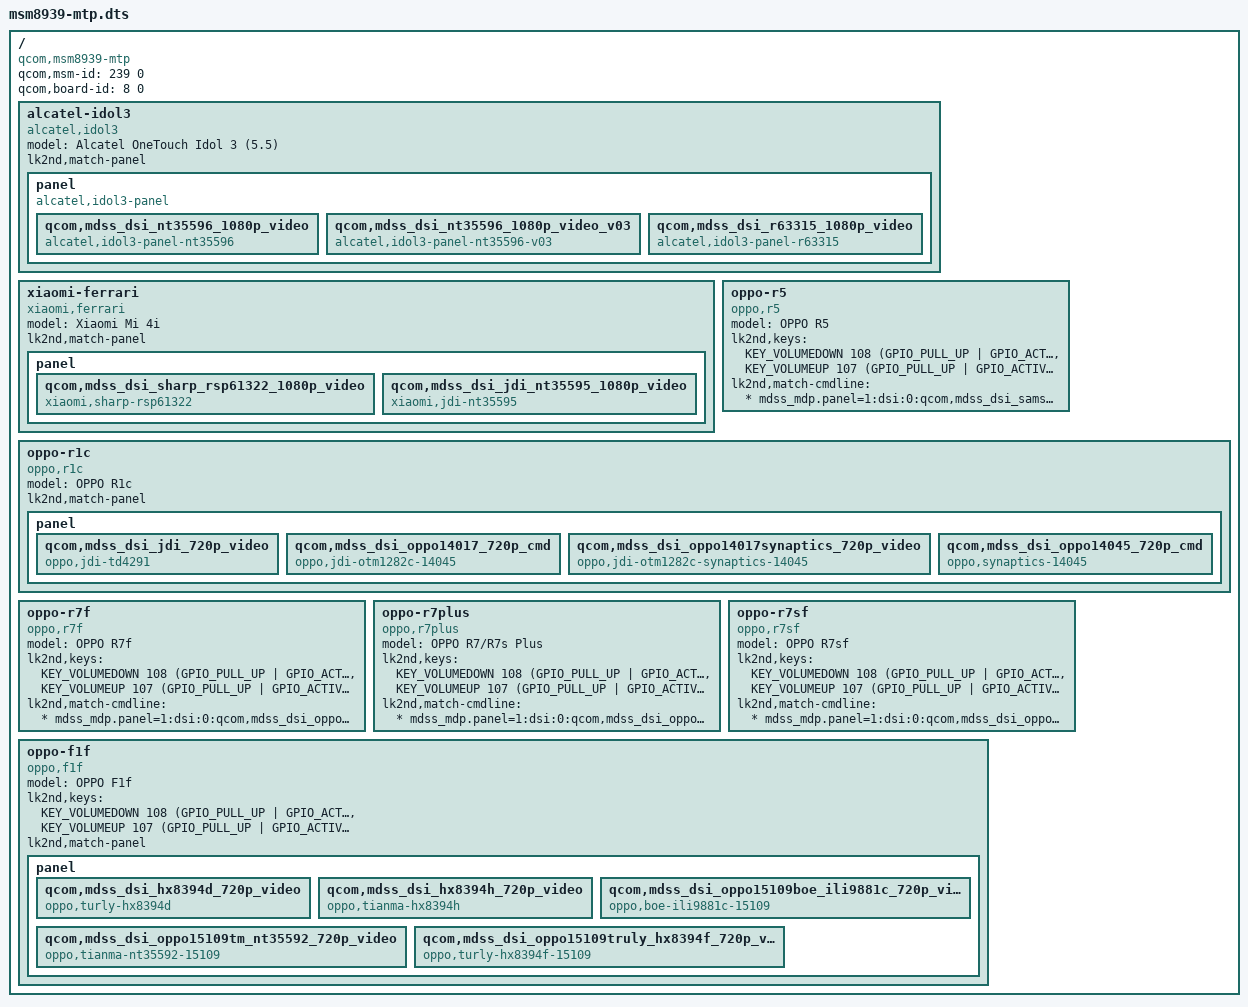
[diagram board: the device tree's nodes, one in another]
// SPDX-License-Identifier: GPL-2.0-only

/dts-v1/;

#include <skeleton.dtsi>
#include <lk2nd.h>

/ {
	compatible = "qcom,msm8939-mtp", "qcom,msm8939";
	qcom,msm-id = <239 0>;
	qcom,board-id = <8 0>;

	alcatel-idol3 {
		model = "Alcatel OneTouch Idol 3 (5.5)";
		compatible = "alcatel,idol3", "qcom,msm8939", "lk2nd,device";
		lk2nd,match-panel;

		panel {
			compatible = "alcatel,idol3-panel";

			qcom,mdss_dsi_nt35596_1080p_video {
				compatible = "alcatel,idol3-panel-nt35596";
			};
			qcom,mdss_dsi_nt35596_1080p_video_v03 {
				compatible = "alcatel,idol3-panel-nt35596-v03";
			};
			qcom,mdss_dsi_r63315_1080p_video {
				compatible = "alcatel,idol3-panel-r63315";
			};
		};
	};

	xiaomi-ferrari {
		model = "Xiaomi Mi 4i";
		compatible = "xiaomi,ferrari", "qcom,msm8939", "lk2nd,device";
		lk2nd,match-panel;

		panel {
			qcom,mdss_dsi_sharp_rsp61322_1080p_video {
				compatible = "xiaomi,sharp-rsp61322";
			};

			qcom,mdss_dsi_jdi_nt35595_1080p_video {
				compatible = "xiaomi,jdi-nt35595";
			};
		};
	};

	oppo-r5 { /* 14005 */
		model = "OPPO R5";
		compatible = "oppo,r5", "qcom,msm8939", "lk2nd,device";
		lk2nd,keys =
			<KEY_VOLUMEDOWN 108 (GPIO_PULL_UP | GPIO_ACTIVE_LOW)>,
			<KEY_VOLUMEUP   107 (GPIO_PULL_UP | GPIO_ACTIVE_LOW)>;
		lk2nd,match-cmdline = "* mdss_mdp.panel=1:dsi:0:qcom,mdss_dsi_samsung_ams520bq04_s6e3fa2x01_1080p_cmd*";
	};

	oppo-r1c { /* 14045 */
		model = "OPPO R1c";
		compatible = "oppo,r1c", "qcom,msm8939", "lk2nd,device";
		lk2nd,match-panel;

		panel {
			qcom,mdss_dsi_jdi_720p_video {
				compatible = "oppo,jdi-td4291";
			};

			qcom,mdss_dsi_oppo14017_720p_cmd {
				compatible = "oppo,jdi-otm1282c-14045";
			};

			qcom,mdss_dsi_oppo14017synaptics_720p_video {
				compatible = "oppo,jdi-otm1282c-synaptics-14045";
			};

			qcom,mdss_dsi_oppo14045_720p_cmd {
				compatible = "oppo,synaptics-14045";
			};
		};
	};

	oppo-r7f { /* 15011 */
		model = "OPPO R7f";
		compatible = "oppo,r7f", "qcom,msm8939", "lk2nd,device";
		lk2nd,keys =
			<KEY_VOLUMEDOWN	108 (GPIO_PULL_UP | GPIO_ACTIVE_LOW)>,
			<KEY_VOLUMEUP	107 (GPIO_PULL_UP | GPIO_ACTIVE_LOW)>;
		lk2nd,match-cmdline = "* mdss_mdp.panel=1:dsi:0:qcom,mdss_dsi_oppo15011samsung_s6e3fa3_1080p_cmd*";
	};

	oppo-r7plus { /* 15018 */
		model = "OPPO R7/R7s Plus";
		compatible = "oppo,r7plus", "qcom,msm8939", "lk2nd,device";
		lk2nd,keys =
			<KEY_VOLUMEDOWN	108 (GPIO_PULL_UP | GPIO_ACTIVE_LOW)>,
			<KEY_VOLUMEUP	107 (GPIO_PULL_UP | GPIO_ACTIVE_LOW)>;
		lk2nd,match-cmdline = "* mdss_mdp.panel=1:dsi:0:qcom,mdss_dsi_oppo15018samsung_s6e3fa3_1080p_cmd*";
	};

	oppo-r7sf { /* 15022 */
		model = "OPPO R7sf";
		compatible = "oppo,r7sf", "qcom,msm8939", "lk2nd,device";
		lk2nd,keys =
			<KEY_VOLUMEDOWN	108 (GPIO_PULL_UP | GPIO_ACTIVE_LOW)>,
			<KEY_VOLUMEUP	107 (GPIO_PULL_UP | GPIO_ACTIVE_LOW)>;
		lk2nd,match-cmdline = "* mdss_mdp.panel=1:dsi:0:qcom,mdss_dsi_oppo15023samsung_s6e3fa3_1080p_cmd*";
	};

	oppo-f1f { /* 15109 */
		model = "OPPO F1f";
		compatible = "oppo,f1f", "qcom,msm8939", "lk2nd,device";
		lk2nd,keys =
			<KEY_VOLUMEDOWN	108 (GPIO_PULL_UP | GPIO_ACTIVE_LOW)>,
			<KEY_VOLUMEUP	107 (GPIO_PULL_UP | GPIO_ACTIVE_LOW)>;
		lk2nd,match-panel;

		panel {
			qcom,mdss_dsi_hx8394d_720p_video {
				compatible = "oppo,turly-hx8394d";
			};

			qcom,mdss_dsi_hx8394h_720p_video {
				compatible = "oppo,tianma-hx8394h";
			};

			qcom,mdss_dsi_oppo15109boe_ili9881c_720p_video {
				compatible = "oppo,boe-ili9881c-15109";
			};

			qcom,mdss_dsi_oppo15109tm_nt35592_720p_video {
				compatible = "oppo,tianma-nt35592-15109";
			};

			qcom,mdss_dsi_oppo15109truly_hx8394f_720p_video {
				compatible = "oppo,turly-hx8394f-15109";
			};
		};
	};
};
